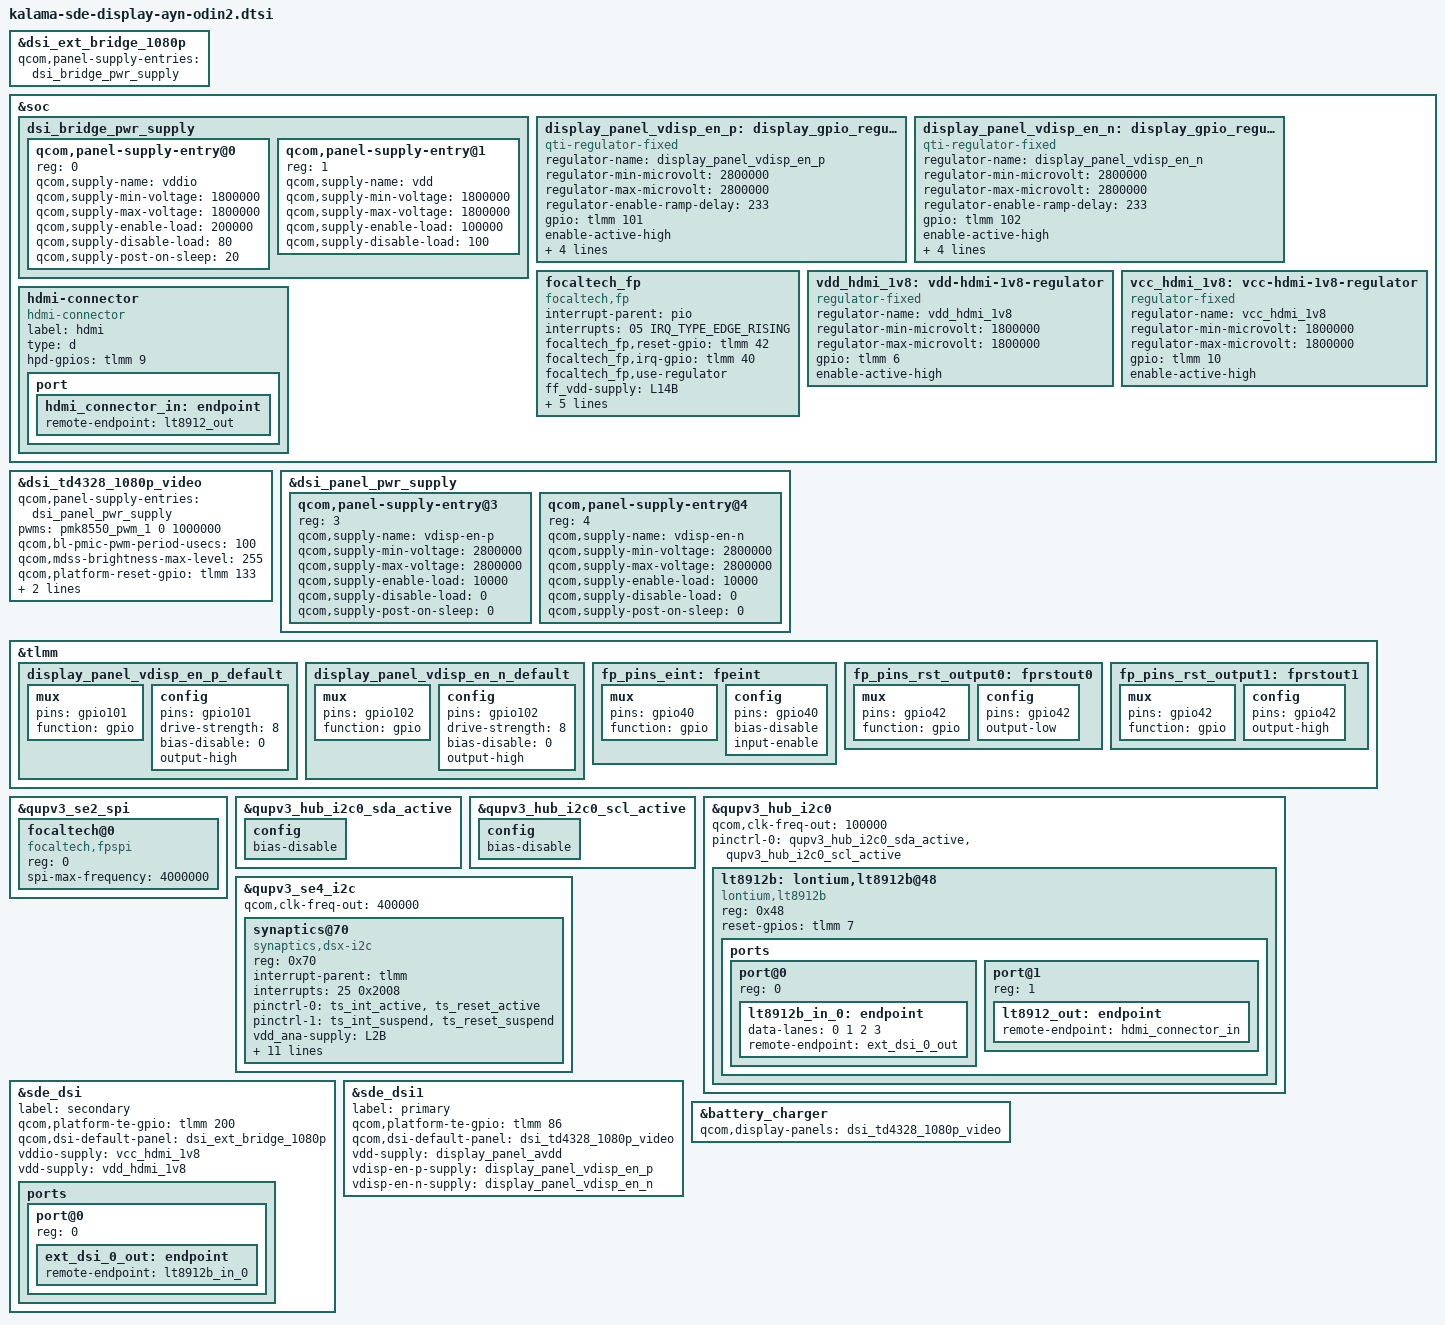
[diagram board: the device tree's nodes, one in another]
#include <dt-bindings/gpio/gpio.h>

#include "kalama-sde-display-ayn-odin2-common.dtsi"

&dsi_ext_bridge_1080p {
	qcom,panel-supply-entries = <&dsi_bridge_pwr_supply>;
};

&soc {
	dsi_bridge_pwr_supply: dsi_bridge_pwr_supply {
		#address-cells = <1>;
		#size-cells = <0>;

		qcom,panel-supply-entry@0 {
			reg = <0>;
			qcom,supply-name = "vddio";
			qcom,supply-min-voltage = <1800000>;
			qcom,supply-max-voltage = <1800000>;
			qcom,supply-enable-load = <200000>;
			qcom,supply-disable-load = <80>;
			qcom,supply-post-on-sleep = <20>;
		};

		qcom,panel-supply-entry@1 {
			reg = <1>;
			qcom,supply-name = "vdd";
			qcom,supply-min-voltage = <1800000>;
			qcom,supply-max-voltage = <1800000>;
			qcom,supply-enable-load = <100000>;
			qcom,supply-disable-load = <100>;
		};
	};
};

&dsi_td4328_1080p_video {
	qcom,panel-supply-entries = <&dsi_panel_pwr_supply>;
	pwms = <&pmk8550_pwm_1 0 1000000>;
	qcom,bl-pmic-pwm-period-usecs = <100>;
	qcom,mdss-brightness-max-level = <255>;
	qcom,platform-reset-gpio = <&tlmm 133 0>;
	qcom,platform-vdisp-en-p = <&tlmm 101 0>;
	qcom,platform-vdisp-en-n = <&tlmm 102 0>;
};

&dsi_panel_pwr_supply {
	qcom,panel-supply-entry@3 {
		reg = <3>;
		qcom,supply-name = "vdisp-en-p";
		qcom,supply-min-voltage = <2800000>;
		qcom,supply-max-voltage = <2800000>;
		qcom,supply-enable-load = <10000>;
		qcom,supply-disable-load = <0>;
		qcom,supply-post-on-sleep = <0>;
	};

	qcom,panel-supply-entry@4 {
		reg = <4>;
		qcom,supply-name = "vdisp-en-n";
		qcom,supply-min-voltage = <2800000>;
		qcom,supply-max-voltage = <2800000>;
		qcom,supply-enable-load = <10000>;
		qcom,supply-disable-load = <0>;
		qcom,supply-post-on-sleep = <0>;
	};
};

&tlmm {
	display_panel_vdisp_en_p_default: display_panel_vdisp_en_p_default {
		mux {
			pins = "gpio101";
			function = "gpio";
		};
		config {
			pins = "gpio101";
			drive-strength = <8>;
			bias-disable = <0>;
			output-high;
		};
	};

	display_panel_vdisp_en_n_default: display_panel_vdisp_en_n_default {
		mux {
			pins = "gpio102";
			function = "gpio";
		};
		config {
			pins = "gpio102";
			drive-strength = <8>;
			bias-disable = <0>;
			output-high;
		};
	};

	fp_pins_eint: fpeint {
		mux {
			pins = "gpio40";
			function = "gpio";
		};

		config {
			pins = "gpio40";
			bias-disable;
			input-enable;
		};
	};

	fp_pins_rst_output0: fprstout0 {
		mux {
			pins = "gpio42";
			function = "gpio";
		};

		config {
			pins = "gpio42";
			output-low;
		};
	};

	fp_pins_rst_output1: fprstout1 {
		mux {
			pins = "gpio42";
			function = "gpio";
		};

		config {
			pins = "gpio42";
			output-high;
		};
	};
};

&soc {
	display_panel_vdisp_en_p: display_gpio_regulator@2 {
		compatible = "qti-regulator-fixed";
		regulator-name = "display_panel_vdisp_en_p";
		regulator-min-microvolt = <2800000>;
		regulator-max-microvolt = <2800000>;
		regulator-enable-ramp-delay = <233>;
		gpio = <&tlmm 101 0>;
		enable-active-high;
		regulator-boot-on;
		proxy-supply = <&display_panel_vdisp_en_p>;
		qcom,proxy-consumer-enable;
		pinctrl-names = "default";
		pinctrl-0 = <&display_panel_vdisp_en_p_default>;
	};

	display_panel_vdisp_en_n: display_gpio_regulator@3 {
		compatible = "qti-regulator-fixed";
		regulator-name = "display_panel_vdisp_en_n";
		regulator-min-microvolt = <2800000>;
		regulator-max-microvolt = <2800000>;
		regulator-enable-ramp-delay = <233>;
		gpio = <&tlmm 102 0>;
		enable-active-high;
		regulator-boot-on;
		proxy-supply = <&display_panel_vdisp_en_n>;
		qcom,proxy-consumer-enable;
		pinctrl-names = "default";
		pinctrl-0 = <&display_panel_vdisp_en_n_default>;
	};

	focaltech_fp: focaltech_fp {
		compatible = "focaltech,fp";
		interrupt-parent = <&pio>;
		interrupts = <05 IRQ_TYPE_EDGE_RISING>;

		focaltech_fp,reset-gpio = <&tlmm 42 0>;
		focaltech_fp,irq-gpio = <&tlmm 40 0>;
		focaltech_fp,use-regulator;

		ff_vdd-supply = <&L14B>;

		focaltech_fp,read-chip;

		pinctrl-names = "ff_pins_reset_low","ff_pins_reset_high","ff_pins_irq_as_int";
		pinctrl-0 = <&fp_pins_rst_output0>;
		pinctrl-1 = <&fp_pins_rst_output1>;
		pinctrl-2 = <&fp_pins_eint>;
		panel = <&dsi_td4328_1080p_video>;
	};

	vdd_hdmi_1v8: vdd-hdmi-1v8-regulator {
		compatible = "regulator-fixed";
		regulator-name = "vdd_hdmi_1v8";
		regulator-min-microvolt = <1800000>;
		regulator-max-microvolt = <1800000>;
		gpio = <&tlmm 6 GPIO_ACTIVE_HIGH>;
		enable-active-high;
	};

	vcc_hdmi_1v8: vcc-hdmi-1v8-regulator {
		compatible = "regulator-fixed";
		regulator-name = "vcc_hdmi_1v8";
		regulator-min-microvolt = <1800000>;
		regulator-max-microvolt = <1800000>;
		gpio = <&tlmm 10 GPIO_ACTIVE_HIGH>;
		enable-active-high;
	};

	hdmi-connector {
		compatible = "hdmi-connector";
		label = "hdmi";
		type = "d";

		hpd-gpios = <&tlmm 9 GPIO_ACTIVE_HIGH>;

		port {
			hdmi_connector_in: endpoint {
				remote-endpoint = <&lt8912_out>;
			};
		};
	};
};

&qupv3_se2_spi {
	status = "okay";
	focaltech@0 {
		compatible = "focaltech,fpspi";
		reg = <0>;
		spi-max-frequency = <4000000>;
		status = "okay";
	};
};

&qupv3_hub_i2c0_sda_active {
	config {
		bias-disable;
	};
};

&qupv3_hub_i2c0_scl_active {
	config {
		bias-disable;
	};
};

&qupv3_hub_i2c0 {
	status = "okay";

	qcom,clk-freq-out = <100000>;

	pinctrl-names = "default";
	pinctrl-0 = <&qupv3_hub_i2c0_sda_active>, <&qupv3_hub_i2c0_scl_active>;
	/delete-property/ pinctrl-1;

	lt8912b: lontium,lt8912b@48 {
		compatible = "lontium,lt8912b";
		reg = <0x48>;
		reset-gpios = <&tlmm 7 0x0>;

/*
		interrupt-parent = <&tlmm>;
		interrupts = <44 0>;
		interrupt-names = "lt_irq";
		lt,irq-gpio = <&tlmm 8 0x2008>;
*/

		ports {
			#address-cells = <1>;
			#size-cells = <0>;

			port@0 {
				reg = <0>;

				lt8912b_in_0: endpoint {
					data-lanes = <0 1 2 3>;
					remote-endpoint = <&ext_dsi_0_out>;
				};
			};

			port@1 {
				reg = <1>;

				lt8912_out: endpoint {
					remote-endpoint = <&hdmi_connector_in>;
				};
			};
		};
	};
};

&qupv3_se4_i2c {
	#address-cells = <1>;
	#size-cells = <0>;

	qcom,clk-freq-out = <400000>;
	status = "okay";

	synaptics@70 {
		compatible = "synaptics,dsx-i2c";
		reg = <0x70>;
		interrupt-parent = <&tlmm>;
		interrupts = <25 0x2008>;
		pinctrl-names = "pmx_ts_active", "pmx_ts_suspend";
		pinctrl-0 = <&ts_int_active &ts_reset_active>;
		pinctrl-1 = <&ts_int_suspend &ts_reset_suspend>;
		vdd_ana-supply = <&L2B>;
		vcc_i2c-supply  = <&L12B>;
		synaptics,pwr-reg-name = "vdd_ana";
		synaptics,bus-reg-name = "vcc_i2c";
		synaptics,ub-i2c-addr = <0x20>;
		/* IRQF_ONESHOT | IRQF_TRIGGER_LOW */
		synaptics,irq-gpio = <&tlmm 25 0x2008>;
		synaptics,irq-on-state = <0>;
		synaptics,power-delay-ms = <200>;
		synaptics,reset-gpio = <&tlmm 24 0x0>;
		synaptics,reset-delay-ms = <200>;
		synaptics,reset-on-state = <0>;
		synaptics,reset-active-ms = <20>;
	};
};

&sde_dsi {
	label = "secondary";

	qcom,platform-te-gpio = <&tlmm 200 0>;

	qcom,dsi-default-panel = <&dsi_ext_bridge_1080p>;

	vddio-supply = <&vcc_hdmi_1v8>;
	vdd-supply = <&vdd_hdmi_1v8>;

	ports {
		#address-cells = <1>;
		#size-cells = <0>;

		port@0 {
			reg = <0>;
			ext_dsi_0_out: endpoint {
				remote-endpoint = <&lt8912b_in_0>;
			};
		};
	};
};

&sde_dsi1 {
	label = "primary";

	qcom,platform-te-gpio = <&tlmm 86 0>;

	qcom,dsi-default-panel = <&dsi_td4328_1080p_video>;

	vdd-supply = <&display_panel_avdd>;
	vdisp-en-p-supply = <&display_panel_vdisp_en_p>;
	vdisp-en-n-supply = <&display_panel_vdisp_en_n>;
};

&battery_charger {
	qcom,display-panels = <&dsi_td4328_1080p_video>;
};
